# STM0_CXSTM register map
Vendor: Texas Instruments
Peripheral module from a debugger description file (folder am243x).
Registers are 32-bit, read-only, reset 0x0 unless marked. A register's access mark holds for its fields unless they carry their own. Offsets are as the file gives them; lines under a group give offsets from that group; [hi:lo] are bit positions; {n}, {i} and the like mark numbered series; 'fields as' and 'values as' point back to an identical list; <NAME> marks a mode.

## STM0_CXSTM
0xC04 VBUSP2APB_WRAP__CXSTM_CFG__STM_REGS_STMDMASTARTR wo — This write-only register is used to start a DMA transfer.<p/>A write of one when the DMA peripheral request interface is idle starts a DMA transfer. A write of zero has no effect. A write of one when the DMA peripheral request interface is active has no effect.
  [0] START
0xC08 VBUSP2APB_WRAP__CXSTM_CFG__STM_REGS_STMDMASTOPR wo — This write-only register is used to stop a DMA transfer.<p/>A write of one stops an active DMA transfer. A write of zero has no effect. A write of one when the DMA peripheral request interface is idle has no effect.
  [0] STOP
0xC0C VBUSP2APB_WRAP__CXSTM_CFG__STM_REGS_STMDMASTATR — This read-only register is used to determine the status of the DMA peripheral request interface.
  [0] STATUS
0xC10 VBUSP2APB_WRAP__CXSTM_CFG__STM_REGS_STMDMACTLR rw — Controls the DMA transfer request mechanism.
  [3:2] SENS
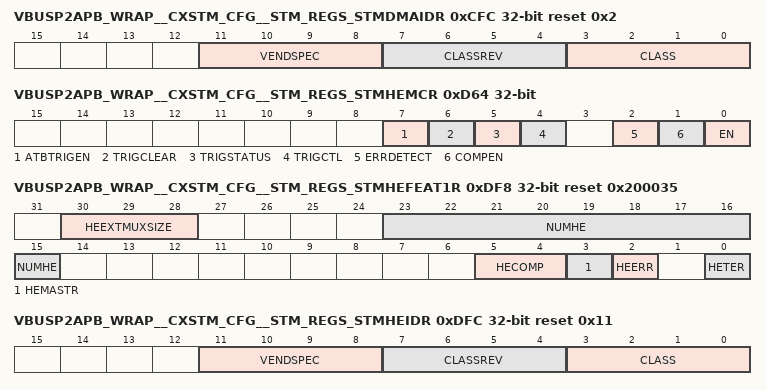
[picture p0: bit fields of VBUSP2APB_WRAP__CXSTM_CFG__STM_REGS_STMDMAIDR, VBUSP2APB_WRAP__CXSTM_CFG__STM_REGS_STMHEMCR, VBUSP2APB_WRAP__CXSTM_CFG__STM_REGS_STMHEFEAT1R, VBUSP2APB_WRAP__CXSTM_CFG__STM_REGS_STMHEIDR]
0xCFC VBUSP2APB_WRAP__CXSTM_CFG__STM_REGS_STMDMAIDR reset 0x2 — This read-only register indicates the DMA features of the STM
  [11:8] VENDSPEC, [7:4] CLASSREV, [3:0] CLASS
0xD00 VBUSP2APB_WRAP__CXSTM_CFG__STM_REGS_STMHEER rw — This read/write register is used to enable hardware events to generate trace.<p/>The register defined one bit per hardware event. Writing 1 enables the appropriate hardware event, writing 0 disables the appropriate hardware event.
  [31:0] HEE
0xD20 VBUSP2APB_WRAP__CXSTM_CFG__STM_REGS_STMHETER rw — This register is used to enable trigger generation on hardware events.
  [31:0] HETE
0xD60 VBUSP2APB_WRAP__CXSTM_CFG__STM_REGS_STMHEBSR rw — This register is used to select the Hardware Event bank
  [0] HEBS
0xD64 VBUSP2APB_WRAP__CXSTM_CFG__STM_REGS_STMHEMCR access per field — This register is used to control the primary functions of Hardware Event tracing.
  [7] ATBTRIGEN rw, [6] TRIGCLEAR wo, [5] TRIGSTATUS ro, [4] TRIGCTL rw, [2] ERRDETECT ro, [1] COMPEN rw, [0] EN rw
0xD68 VBUSP2APB_WRAP__CXSTM_CFG__STM_REGS_STMHEEXTMUXR rw — This register is used to control hardware event multiplexors external to the STM
  [7:0] EXTMUX
0xDF4 VBUSP2APB_WRAP__CXSTM_CFG__STM_REGS_STMHEMASTR reset 0x80 — Indicates the STPv2 master number of hardware event trace. This number is the master number presented in STPv2.
  [15:0] MASTER
0xDF8 VBUSP2APB_WRAP__CXSTM_CFG__STM_REGS_STMHEFEAT1R reset 0x200035 — Indicates the features of the STM.
  [30:28] HEEXTMUXSIZE, [23:15] NUMHE, [5:4] HECOMP, [3] HEMASTR, [2] HEERR, [0] HETER
0xDFC VBUSP2APB_WRAP__CXSTM_CFG__STM_REGS_STMHEIDR reset 0x11 — Indicates the features of hardware event tracing in the STM.
  [11:8] VENDSPEC, [7:4] CLASSREV, [3:0] CLASS
0xE00 VBUSP2APB_WRAP__CXSTM_CFG__STM_REGS_STMSPER rw — This read/write only register is used to enable the stimulus registers to generate trace.<p/>The register defines one bit per stimulus register. Writing 1 enables the appropriate stimulus port, writing 0 disables the appropriate stimulus port. This register is used in conjunction with the Software Enable Bank Select Register.
  [31:0] SPE
0xE20 VBUSP2APB_WRAP__CXSTM_CFG__STM_REGS_STMSPTER rw — This register is used to enable trigger generation on writes to enabled stimulus port registers.
  [31:0] SPTE
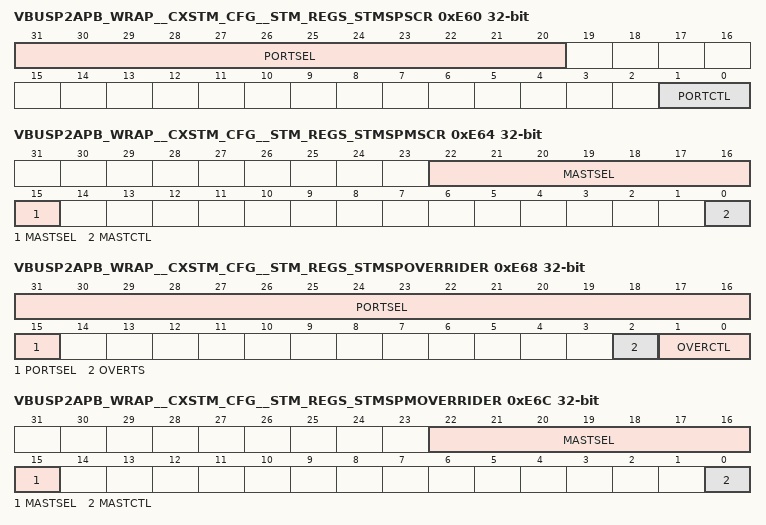
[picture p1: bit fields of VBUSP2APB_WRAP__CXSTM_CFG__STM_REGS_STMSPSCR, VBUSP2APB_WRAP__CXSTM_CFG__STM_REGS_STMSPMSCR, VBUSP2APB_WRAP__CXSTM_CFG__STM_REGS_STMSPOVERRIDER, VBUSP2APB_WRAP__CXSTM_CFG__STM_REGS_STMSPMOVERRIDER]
0xE60 VBUSP2APB_WRAP__CXSTM_CFG__STM_REGS_STMSPSCR rw — This register allows a debugger to program which stimulus ports the STMSPER and STMSPTER apply to.
  [31:20] PORTSEL, [1:0] PORTCTL
0xE64 VBUSP2APB_WRAP__CXSTM_CFG__STM_REGS_STMSPMSCR rw — This register allows a debugger to program which masters the STMSPSCR applies to.
  [22:15] MASTSEL, [0] MASTCTL
0xE68 VBUSP2APB_WRAP__CXSTM_CFG__STM_REGS_STMSPOVERRIDER rw — This register allows a debugger to override various features of the STM.
  [31:15] PORTSEL, [2] OVERTS, [1:0] OVERCTL
0xE6C VBUSP2APB_WRAP__CXSTM_CFG__STM_REGS_STMSPMOVERRIDER rw — This register allows a debugger to choose which masters the STMSPOVERRIDERR applies to.
  [22:15] MASTSEL, [0] MASTCTL
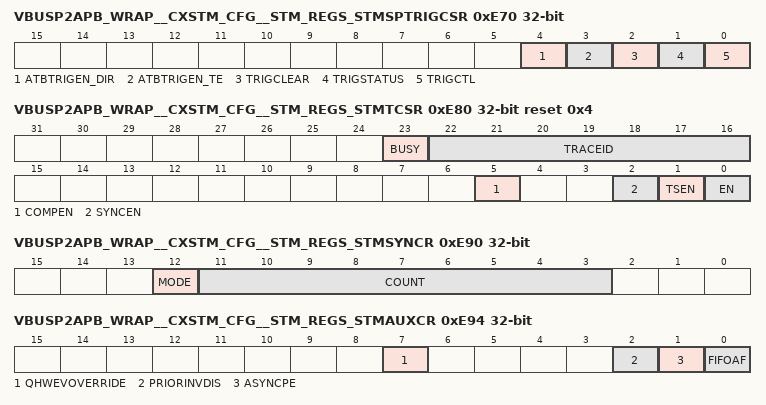
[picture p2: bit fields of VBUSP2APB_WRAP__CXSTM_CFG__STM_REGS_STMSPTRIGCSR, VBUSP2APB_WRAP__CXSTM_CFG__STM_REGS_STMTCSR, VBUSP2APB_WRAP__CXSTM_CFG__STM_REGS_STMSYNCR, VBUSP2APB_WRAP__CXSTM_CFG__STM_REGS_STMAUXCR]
0xE70 VBUSP2APB_WRAP__CXSTM_CFG__STM_REGS_STMSPTRIGCSR access per field — This register is used to control the STM triggers caused by STMSPTER.
  [4] ATBTRIGEN_DIR rw, [3] ATBTRIGEN_TE rw, [2] TRIGCLEAR wo, [1] TRIGSTATUS ro, [0] TRIGCTL rw
0xE80 VBUSP2APB_WRAP__CXSTM_CFG__STM_REGS_STMTCSR access per field reset 0x4 — Controls the STM settings.
  [23] BUSY ro, [22:16] TRACEID rw, [5] COMPEN rw, [2] SYNCEN ro, [1] TSEN rw, [0] EN rw
0xE84 VBUSP2APB_WRAP__CXSTM_CFG__STM_REGS_STMTSSTIMR wo — This write-only register is used to force the next packet caused by a stimulus port write to have a timestamp output.
  [0] FORCETS
0xE8C VBUSP2APB_WRAP__CXSTM_CFG__STM_REGS_STMTSFREQR rw — This read-write register is used to indicate the frequency of the timestamp counter. The unit of measurement is increments per second. When the STPv2 protocol is used, this register contains the value output in the FREQ and FREQ_TS packets. The timestamp frequency is output in the STPv2 protocol at every synchronization point when STMTCSR.TSEN is b1.
  [31:0] FREQ
0xE90 VBUSP2APB_WRAP__CXSTM_CFG__STM_REGS_STMSYNCR rw — This register controls the interval between synchronization packets, in terms of the number of bytes of trace generated.<p/>This register only provides a hint of the desired synchronization frequency, implementations are permitted to be inaccurate.<p/>Writing a value of 0x00000000 to this register disables the synchronization counter however any other IMPLEMENTATION DEFINED synchronizations mechanism continue to operate independently.
  [12] MODE, [11:3] COUNT
0xE94 VBUSP2APB_WRAP__CXSTM_CFG__STM_REGS_STMAUXCR rw — Used for IMPLEMENTATION DEFINED STM controls.
  [7] QHWEVOVERRIDE, [2] PRIORINVDIS, [1] ASYNCPE, [0] FIFOAF
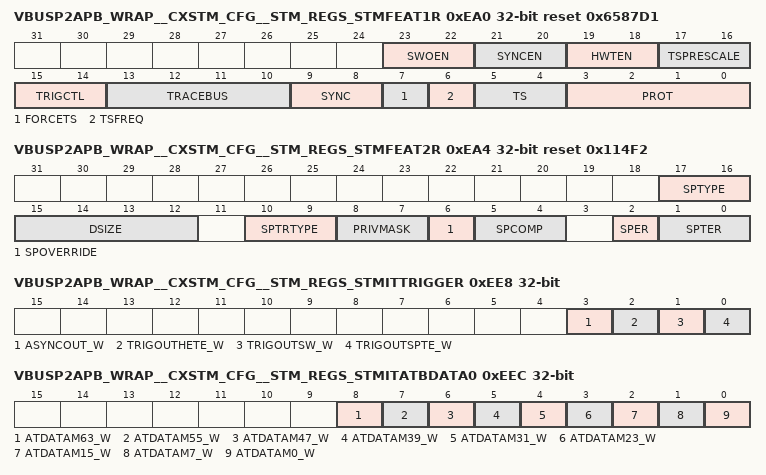
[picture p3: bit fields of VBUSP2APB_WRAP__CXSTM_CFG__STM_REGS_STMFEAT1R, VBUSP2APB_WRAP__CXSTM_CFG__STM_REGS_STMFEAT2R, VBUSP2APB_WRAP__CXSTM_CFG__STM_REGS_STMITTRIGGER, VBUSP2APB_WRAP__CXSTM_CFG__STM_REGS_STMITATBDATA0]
0xEA0 VBUSP2APB_WRAP__CXSTM_CFG__STM_REGS_STMFEAT1R reset 0x6587D1 — Indicates the features of the STM.
  [23:22] SWOEN, [21:20] SYNCEN, [19:18] HWTEN, [17:16] TSPRESCALE, [15:14] TRIGCTL, [13:10] TRACEBUS, [9:8] SYNC, [7] FORCETS, [6] TSFREQ, [5:4] TS, [3:0] PROT
0xEA4 VBUSP2APB_WRAP__CXSTM_CFG__STM_REGS_STMFEAT2R reset 0x114F2 — Indicates the features of the STM.
  [17:16] SPTYPE, [15:12] DSIZE, [10:9] SPTRTYPE, [8:7] PRIVMASK, [6] SPOVERRIDE, [5:4] SPCOMP, [2] SPER, [1:0] SPTER
0xEA8 VBUSP2APB_WRAP__CXSTM_CFG__STM_REGS_STMFEAT3R reset 0x7F — Indicates the features of the STM.
  [6:0] NUMMAST
0xEE8 VBUSP2APB_WRAP__CXSTM_CFG__STM_REGS_STMITTRIGGER wo — Integration Test for Cross-Trigger Outputs Register
  [3] ASYNCOUT_W, [2] TRIGOUTHETE_W, [1] TRIGOUTSW_W, [0] TRIGOUTSPTE_W
0xEEC VBUSP2APB_WRAP__CXSTM_CFG__STM_REGS_STMITATBDATA0 wo — Controls the value of the ATDATAM output in integration mode:
  [8] ATDATAM63_W, [7] ATDATAM55_W, [6] ATDATAM47_W, [5] ATDATAM39_W, [4] ATDATAM31_W, [3] ATDATAM23_W, [2] ATDATAM15_W, [1] ATDATAM7_W, [0] ATDATAM0_W
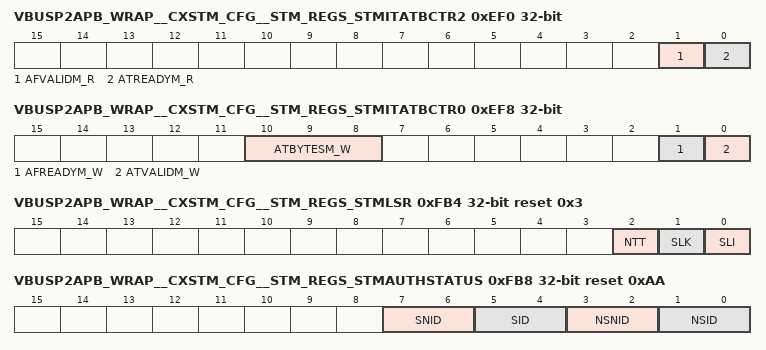
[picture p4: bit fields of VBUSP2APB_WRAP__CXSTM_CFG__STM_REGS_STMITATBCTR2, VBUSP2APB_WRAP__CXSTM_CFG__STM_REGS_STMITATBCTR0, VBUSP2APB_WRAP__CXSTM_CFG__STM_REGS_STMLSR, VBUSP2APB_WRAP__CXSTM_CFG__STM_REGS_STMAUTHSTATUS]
0xEF0 VBUSP2APB_WRAP__CXSTM_CFG__STM_REGS_STMITATBCTR2 — Returns the value of the ATREADYM and AFVALIDM inputs in integration mode.
  [1] AFVALIDM_R, [0] ATREADYM_R
0xEF4 VBUSP2APB_WRAP__CXSTM_CFG__STM_REGS_STMITATBID wo — Controls the value of the ATIDM output in integration mode.
  [6:0] ATIDM_W
0xEF8 VBUSP2APB_WRAP__CXSTM_CFG__STM_REGS_STMITATBCTR0 wo — Controls the value of the ATVALIDM, AFREADYM, and ATBYTESM outputs in integration mode.
  [10:8] ATBYTESM_W, [1] AFREADYM_W, [0] ATVALIDM_W
0xF00 VBUSP2APB_WRAP__CXSTM_CFG__STM_REGS_STMITCTRL rw — Used to enable topology detection. See the CoreSight Architecture Specification for more information. This register enables the component to switch between functional mode and integration mode. The default behavior is functional mode. In integration mode the inputs and outputs of the STM can be directly controlled for integration testing and topology solving. <p/>Note: When a device has been in integration mode, it might not function with the original behavior. After performing integration or topology detection, you must reset the system to ensure correct behavior of CoreSight and other connected system components that are affected by the integration or topology detection.
  [0] IME
0xFA0 VBUSP2APB_WRAP__CXSTM_CFG__STM_REGS_STMCLAIMSET reset 0xF — This is used in conjunction with Claim Tag Clear Register, STMCLAIMCLR. This register forms one half of the Claim Tag value. This location allows individual bits to be set, write, and returns the number of bits that can be set, read.
  [3:0] SET
0xFA4 VBUSP2APB_WRAP__CXSTM_CFG__STM_REGS_STMCLAIMCLR — This register is used in conjunction with Claim Tag Set Register, STMCLAIMSET. This register forms one half of the Claim Tag value. This location enables individual bits to be cleared, write, and returns the current Claim Tag value, read.
  [3:0] CLR
0xFB0 VBUSP2APB_WRAP__CXSTM_CFG__STM_REGS_STMLAR wo — Enables write access to device registers.
  [31:0] KEY
0xFB4 VBUSP2APB_WRAP__CXSTM_CFG__STM_REGS_STMLSR reset 0x3 — Indicates the status of the lock control mechanism. This lock prevents accidental writes by code under debug. The lock mechanism does not impact accesses to the extended stimulus port registers. This register must always be present although there might not be any lock access control mechanism. The lock mechanism, where present and locked, blocks write accesses to any register, except the STMLAR. The lock mechanism is only present for accesses with the PADDRDBG31 signal LOW.
  [2] NTT, [1] SLK, [0] SLI
0xFB8 VBUSP2APB_WRAP__CXSTM_CFG__STM_REGS_STMAUTHSTATUS reset 0xAA — Reports the required security level and current status of the authentication interface.
  [7:6] SNID, [5:4] SID, [3:2] NSNID, [1:0] NSID
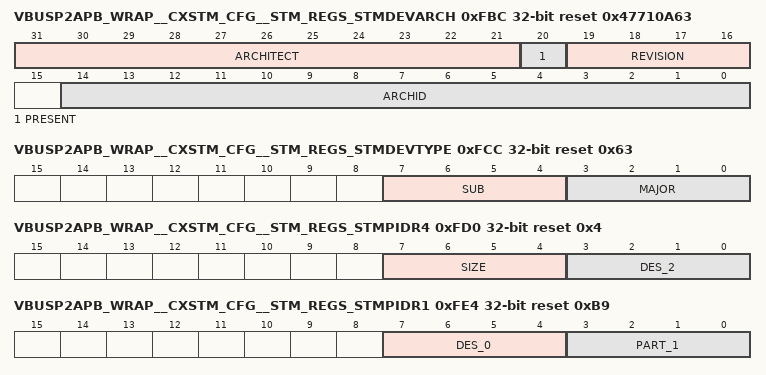
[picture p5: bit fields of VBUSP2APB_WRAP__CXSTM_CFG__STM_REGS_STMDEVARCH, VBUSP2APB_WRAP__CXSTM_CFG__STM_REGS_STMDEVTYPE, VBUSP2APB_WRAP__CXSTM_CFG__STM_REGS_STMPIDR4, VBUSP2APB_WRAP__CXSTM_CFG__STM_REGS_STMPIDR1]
0xFBC VBUSP2APB_WRAP__CXSTM_CFG__STM_REGS_STMDEVARCH reset 0x47710A63 — Indicates the architect and architecture of the STM. For the STM-500, the architect is ARM, and the architecture is STMv1.1
  [31:21] ARCHITECT, [20] PRESENT, [19:16] REVISION, [14:0] ARCHID
0xFC8 VBUSP2APB_WRAP__CXSTM_CFG__STM_REGS_STMDEVID reset 0x10000 — Indicates the capabilities of the CoreSight STM.
  [16:0] NUMSP
0xFCC VBUSP2APB_WRAP__CXSTM_CFG__STM_REGS_STMDEVTYPE reset 0x63 — Provides a debugger with information about the component when the part number is not recognized. The debugger can then report this information.
  [7:4] SUB, [3:0] MAJOR
0xFD0 VBUSP2APB_WRAP__CXSTM_CFG__STM_REGS_STMPIDR4 reset 0x4 — Part of the set of Peripheral Identification registers. Contains part of the designer identity and the memory footprint indicator.
  [7:4] SIZE, [3:0] DES_2
{0xFC0+4i} VBUSP2APB_WRAP__CXSTM_CFG__STM_REGS_STMPIDR{i} access not given reset not defined (i=5..7) — Reserved
0xFE0 VBUSP2APB_WRAP__CXSTM_CFG__STM_REGS_STMPIDR0 reset 0x63 — Part of the set of Peripheral Identification registers. Contains part of the designer specific part number.
  [7:0] PART_0
0xFE4 VBUSP2APB_WRAP__CXSTM_CFG__STM_REGS_STMPIDR1 reset 0xB9 — Part of the set of Peripheral Identification registers. Contains part of the designer specific part number and part of the designer identity.
  [7:4] DES_0, [3:0] PART_1
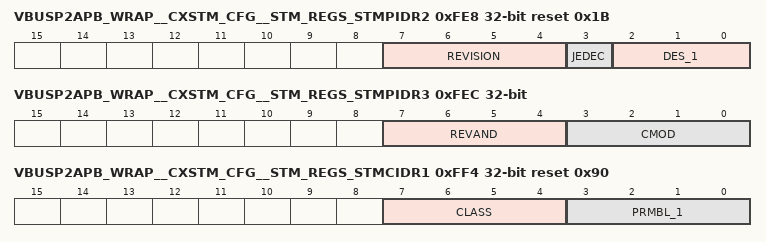
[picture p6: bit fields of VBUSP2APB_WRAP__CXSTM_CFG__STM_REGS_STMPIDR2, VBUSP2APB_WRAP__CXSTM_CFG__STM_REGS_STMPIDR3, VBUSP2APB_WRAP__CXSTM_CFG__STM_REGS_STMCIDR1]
0xFE8 VBUSP2APB_WRAP__CXSTM_CFG__STM_REGS_STMPIDR2 reset 0x1B — Part of the set of Peripheral Identification registers. Contains part of the designer identity and the product revision.
  [7:4] REVISION, [3] JEDEC, [2:0] DES_1
0xFEC VBUSP2APB_WRAP__CXSTM_CFG__STM_REGS_STMPIDR3 — Part of the set of Peripheral Identification registers. Contains the RevAnd and Customer_Modified bit fields.
  [7:4] REVAND, [3:0] CMOD
0xFF0 VBUSP2APB_WRAP__CXSTM_CFG__STM_REGS_STMCIDR0 reset 0xD — A component identification register, that indicates that the identification registers are present.
  [7:0] PRMBL_0
0xFF4 VBUSP2APB_WRAP__CXSTM_CFG__STM_REGS_STMCIDR1 reset 0x90 — A component identification register, that indicates that the identification registers are present. This register also indicates the component class.
  [7:4] CLASS, [3:0] PRMBL_1
0xFF8 VBUSP2APB_WRAP__CXSTM_CFG__STM_REGS_STMCIDR2 reset 0x5 — A component identification register, that indicates that the identification registers are present.
  [7:0] PRMBL_2
0xFFC VBUSP2APB_WRAP__CXSTM_CFG__STM_REGS_STMCIDR3 reset 0xB1 — A component identification register, that indicates that the identification registers are present.
  [7:0] PRMBL_3
